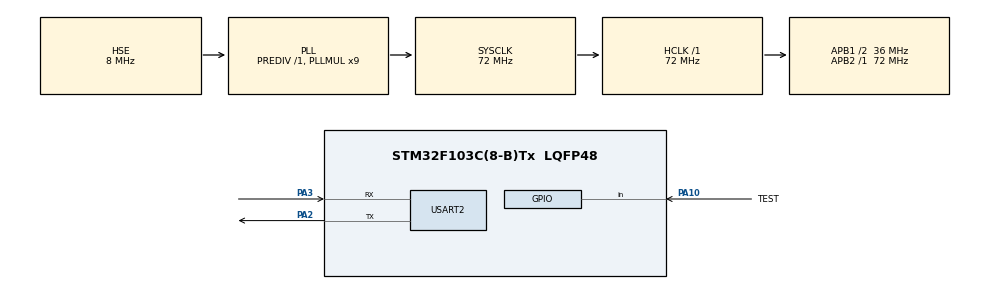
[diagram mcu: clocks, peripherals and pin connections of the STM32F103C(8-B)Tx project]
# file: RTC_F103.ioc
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Mcu.Family=STM32F1
Mcu.Name=STM32F103C(8-B)Tx
Mcu.Package=LQFP48
NVIC.PriorityGroup=NVIC_PRIORITYGROUP_4
PA10.GPIO_Label=TEST
PA10.GPIO_PuPd=GPIO_PULLUP
PA10.Signal=GPIO_Input
PA13.Mode=Serial_Wire
PA13.Signal=SYS_JTMS-SWDIO
PA14.Mode=Serial_Wire
PA14.Signal=SYS_JTCK-SWCLK
PA2.Mode=Asynchronous
PA2.Signal=USART2_TX
PA3.Mode=Asynchronous
PA3.Signal=USART2_RX
PC14-OSC32_IN.Mode=LSE-External-Oscillator
PC14-OSC32_IN.Signal=RCC_OSC32_IN
PC15-OSC32_OUT.Mode=LSE-External-Oscillator
PC15-OSC32_OUT.Signal=RCC_OSC32_OUT
PD0-OSC_IN.Mode=HSE-External-Oscillator
PD0-OSC_IN.Signal=RCC_OSC_IN
PD1-OSC_OUT.Mode=HSE-External-Oscillator
PD1-OSC_OUT.Signal=RCC_OSC_OUT
ProjectManager.HeapSize=0x200
ProjectManager.StackSize=0x400
ProjectManager.TargetToolchain=STM32CubeIDE
RCC.AHBFreq_Value=72000000
RCC.APB1CLKDivider=RCC_HCLK_DIV2
RCC.APB1Freq_Value=36000000
RCC.APB1TimFreq_Value=72000000
RCC.APB2Freq_Value=72000000
RCC.APB2TimFreq_Value=72000000
RCC.HCLKFreq_Value=72000000
RCC.PLLMUL=RCC_PLL_MUL9
RCC.PLLSourceVirtual=RCC_PLLSOURCE_HSE
RCC.RTCClockSelection=RCC_RTCCLKSOURCE_LSE
RCC.SYSCLKFreq_VALUE=72000000
RCC.SYSCLKSource=RCC_SYSCLKSOURCE_PLLCLK
RCC.USBFreq_Value=72000000
RTC.AutoPrediv=RTC_AUTO_1_SECOND
RTC.Date=3
RTC.Format=RTC_FORMAT_BIN
RTC.Hours=23
RTC.Minutes=59
RTC.Month=RTC_MONTH_FEBRUARY
RTC.OutPut=RTC_OUTPUTSOURCE_ALARM
RTC.Seconds=55
RTC.WeekDay=RTC_WEEKDAY_SATURDAY
RTC.Year=20
USART2.VirtualMode=VM_ASYNC
VP_RTC_VS_RTC_Activate.Mode=RTC_Enabled
VP_RTC_VS_RTC_Calendar.Mode=RTC_Calendar
board=custom

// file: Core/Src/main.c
/* USER CODE BEGIN Header */
/**
  ******************************************************************************
  * @file           : main.c
  * @brief          : Main program body
  ******************************************************************************
  * @attention
  *
  * <h2><center>&copy; Copyright (c) 2020 STMicroelectronics.
  * All rights reserved.</center></h2>
  *
  * This software component is licensed by ST under BSD 3-Clause license,
  * the "License"; You may not use this file except in compliance with the
  * License. You may obtain a copy of the License at:
  *                        opensource.org/licenses/BSD-3-Clause
  *
  ******************************************************************************
  *
  *  Created on: 1.02.2019
  *      Author: Mateusz Salamon
  *    www.msalamon.pl
  *
  *      Website: https://msalamon.pl/wbudowany-rtc-w-stm32f1/
  *               https://msalamon.pl/co-ta-data-w-rct-stm32f1/
  *               https://msalamon.pl/zapamietajmy-nastawe-rtc-stm32f1-przy-pomocy-bateryjki-na-vbat-zewnetrzny-kwarc-na-bluepill/
  *      GitHub:  https://github.com/lamik/RTC_F103
  *      Contact: mateusz@msalamon.pl
*/
/* USER CODE END Header */

#include "main.h"
#include "rtc.h"
#include "usart.h"
#include "gpio.h"

/* USER CODE BEGIN Includes */
#include <stdio.h>
/* USER CODE END Includes */

/* USER CODE BEGIN PV */
RTC_TimeTypeDef RtcTime;
RTC_DateTypeDef RtcDate;

uint8_t CompareSeconds;
uint8_t CompareDate;

uint8_t Message[64];
uint8_t MessageLen;

/* USER CODE END PV */

void SystemClock_Config(void);

/* USER CODE BEGIN 0 */
void SetRTC(void);
void BackupDateToBR(void);
/* USER CODE END 0 */

int main(void)
{

  /* MCU Configuration--------------------------------------------------------*/

  /* Reset of all peripherals, Initializes the Flash interface and the Systick. */
  HAL_Init();

  /* Configure the system clock */
  SystemClock_Config();

  /* Initialize all configured peripherals */
  MX_GPIO_Init();
  MX_RTC_Init();
  MX_USART2_UART_Init();

  /* Infinite loop */
  /* USER CODE BEGIN WHILE */
  while (1)
  {
	  HAL_RTC_GetTime(&hrtc, &RtcTime, RTC_FORMAT_BIN);
	  HAL_RTC_GetDate(&hrtc, &RtcDate, RTC_FORMAT_BIN);

	  if(RtcTime.Seconds != CompareSeconds)
	  {
		  MessageLen = sprintf((char*)Message, "Date: %02d.%02d.20%02d Time: %02d:%02d:%02d\n\r", RtcDate.Date, RtcDate.Month, RtcDate.Year, RtcTime.Hours, RtcTime.Minutes, RtcTime.Seconds);
		  HAL_UART_Transmit(&huart2, Message, MessageLen, 100);
		  CompareSeconds = RtcTime.Seconds;
	  }
	  if(RtcDate.Date != CompareDate)
	  {
		  BackupDateToBR();
		  CompareDate = RtcDate.Date;
	  }

	  if(GPIO_PIN_RESET == HAL_GPIO_ReadPin(TEST_GPIO_Port, TEST_Pin))
	  {
		 while(GPIO_PIN_RESET == HAL_GPIO_ReadPin(TEST_GPIO_Port, TEST_Pin))
		 {}
		 SetRTC();
	  }
    /* USER CODE END WHILE */

  }
}

void SystemClock_Config(void)
{
  RCC_OscInitTypeDef RCC_OscInitStruct = {0};
  RCC_ClkInitTypeDef RCC_ClkInitStruct = {0};
  RCC_PeriphCLKInitTypeDef PeriphClkInit = {0};

  /** Initializes the CPU, AHB and APB busses clocks
  */
  RCC_OscInitStruct.OscillatorType = RCC_OSCILLATORTYPE_HSE|RCC_OSCILLATORTYPE_LSE;
  RCC_OscInitStruct.HSEState = RCC_HSE_ON;
  RCC_OscInitStruct.HSEPredivValue = RCC_HSE_PREDIV_DIV1;
  RCC_OscInitStruct.LSEState = RCC_LSE_ON;
  RCC_OscInitStruct.HSIState = RCC_HSI_ON;
  RCC_OscInitStruct.PLL.PLLState = RCC_PLL_ON;
  RCC_OscInitStruct.PLL.PLLSource = RCC_PLLSOURCE_HSE;
  RCC_OscInitStruct.PLL.PLLMUL = RCC_PLL_MUL9;
  if (HAL_RCC_OscConfig(&RCC_OscInitStruct) != HAL_OK)
  {
    Error_Handler();
  }
  /** Initializes the CPU, AHB and APB busses clocks
  */
  RCC_ClkInitStruct.ClockType = RCC_CLOCKTYPE_HCLK|RCC_CLOCKTYPE_SYSCLK
                              |RCC_CLOCKTYPE_PCLK1|RCC_CLOCKTYPE_PCLK2;
  RCC_ClkInitStruct.SYSCLKSource = RCC_SYSCLKSOURCE_PLLCLK;
  RCC_ClkInitStruct.AHBCLKDivider = RCC_SYSCLK_DIV1;
  RCC_ClkInitStruct.APB1CLKDivider = RCC_HCLK_DIV2;
  RCC_ClkInitStruct.APB2CLKDivider = RCC_HCLK_DIV1;

  if (HAL_RCC_ClockConfig(&RCC_ClkInitStruct, FLASH_LATENCY_2) != HAL_OK)
  {
    Error_Handler();
  }
  PeriphClkInit.PeriphClockSelection = RCC_PERIPHCLK_RTC;
  PeriphClkInit.RTCClockSelection = RCC_RTCCLKSOURCE_LSE;
  if (HAL_RCCEx_PeriphCLKConfig(&PeriphClkInit) != HAL_OK)
  {
    Error_Handler();
  }
}

/* USER CODE BEGIN 4 */
void BackupDateToBR(void)
{
	HAL_RTCEx_BKUPWrite(&hrtc, RTC_BKP_DR2, ((RtcDate.Date << 8) | (RtcDate.Month)));
	HAL_RTCEx_BKUPWrite(&hrtc, RTC_BKP_DR3, ((RtcDate.Year << 8) | (RtcDate.WeekDay)));
}

void SetRTC(void)
{
	RTC_TimeTypeDef sTime = {0};
	RTC_DateTypeDef DateToUpdate = {0};

	/** Initialize RTC and set the Time and Date
	*/
	sTime.Hours = 23;
	sTime.Minutes = 59;
	sTime.Seconds = 56;

	if (HAL_RTC_SetTime(&hrtc, &sTime, RTC_FORMAT_BIN) != HAL_OK)
	{
	  Error_Handler();
	}

	DateToUpdate.WeekDay = RTC_WEEKDAY_SATURDAY;
	DateToUpdate.Month = RTC_MONTH_FEBRUARY;
	DateToUpdate.Date = 3;
	DateToUpdate.Year = 20;

	if (HAL_RTC_SetDate(&hrtc, &DateToUpdate, RTC_FORMAT_BIN) != HAL_OK)
	{
	  Error_Handler();
	}

	BackupDateToBR();
}
/* USER CODE END 4 */

void Error_Handler(void)
{
}

/************************ (C) COPYRIGHT STMicroelectronics *****END OF FILE****/
